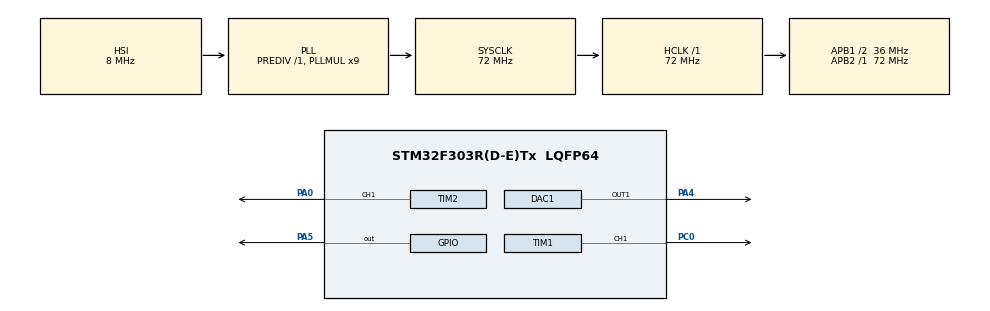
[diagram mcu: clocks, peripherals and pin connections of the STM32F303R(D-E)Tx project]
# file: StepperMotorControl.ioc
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Mcu.Family=STM32F3
Mcu.Name=STM32F303R(D-E)Tx
Mcu.Package=LQFP64
NVIC.PriorityGroup=NVIC_PRIORITYGROUP_4
NVIC.TIM1_CC_IRQn=true\:0\:0\:false\:false\:true\:true\:true\:true
NVIC.TIM6_DAC_IRQn=true\:0\:0\:false\:false\:true\:true\:true\:true
PA0.Signal=S_TIM2_CH1_ETR
PA13.Mode=Serial_Wire
PA13.Signal=SYS_JTMS-SWDIO
PA14.Mode=Serial_Wire
PA14.Signal=SYS_JTCK-SWCLK
PA4.Signal=COMP_DAC11_group
PA5.Signal=GPIO_Output
PC0.Signal=S_TIM1_CH1
PC14-OSC32_IN.Mode=LSE-External-Oscillator
PC14-OSC32_IN.Signal=RCC_OSC32_IN
PC15-OSC32_OUT.Mode=LSE-External-Oscillator
PC15-OSC32_OUT.Signal=RCC_OSC32_OUT
PF0-OSC_IN.Mode=HSE-External-Oscillator
PF0-OSC_IN.Signal=RCC_OSC_IN
PF1-OSC_OUT.Mode=HSE-External-Oscillator
PF1-OSC_OUT.Signal=RCC_OSC_OUT
ProjectManager.HeapSize=0x200
ProjectManager.StackSize=0x400
ProjectManager.TargetToolchain=STM32CubeIDE
RCC.AHBFreq_Value=72000000
RCC.APB1CLKDivider=RCC_HCLK_DIV2
RCC.APB1Freq_Value=36000000
RCC.APB1TimFreq_Value=72000000
RCC.APB2Freq_Value=72000000
RCC.APB2TimFreq_Value=72000000
RCC.CortexFreq_Value=72000000
RCC.HCLKFreq_Value=72000000
RCC.HSE_VALUE=8000000
RCC.HSI_VALUE=8000000
RCC.PLLMUL=RCC_PLL_MUL9
RCC.SYSCLKFreq_VALUE=72000000
RCC.SYSCLKSourceVirtual=RCC_SYSCLKSOURCE_PLLCLK
RCC.USBFreq_Value=72000000
SH.COMP_DAC11_group.0=DAC1_OUT1,DAC_OUT1
SH.S_TIM1_CH1.0=TIM1_CH1,PWM Generation1 CH1
SH.S_TIM2_CH1_ETR.0=TIM2_CH1,PWM Generation1 CH1
TIM1.Channel-PWM\ Generation1\ CH1=TIM_CHANNEL_1
TIM1.Period=999
TIM1.Prescaler=71
TIM1.Pulse-PWM\ Generation1\ CH1=500
TIM2.Channel-PWM\ Generation1\ CH1=TIM_CHANNEL_1
TIM2.Period=999
TIM2.Prescaler=71
TIM2.Pulse-PWM\ Generation1\ CH1=500
VP_TIM1_VS_ClockSourceINT.Mode=Internal
VP_TIM2_VS_ClockSourceINT.Mode=Internal
board=custom

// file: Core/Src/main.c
/* USER CODE BEGIN Header */
/**
  ******************************************************************************
  * @file           : main.c
  * @brief          : Main program body
  ******************************************************************************
  * @attention
  *
  * Copyright (c) 2026 STMicroelectronics.
  * All rights reserved.
  *
  * This software is licensed under terms that can be found in the LICENSE file
  * in the root directory of this software component.
  * If no LICENSE file comes with this software, it is provided AS-IS.
  *
  ******************************************************************************
  */
/* USER CODE END Header */
#include "main.h"

/* USER CODE BEGIN PD */
#define STEPS_PER_DIRECTION  5000U

/* USER CODE END PD */

DAC_HandleTypeDef hdac1;

TIM_HandleTypeDef htim1;
TIM_HandleTypeDef htim2;

/* USER CODE BEGIN PV */
volatile uint32_t step_count = 0;   /* shared with ISR, so volatile */

/* USER CODE END PV */

void SystemClock_Config(void);
static void MX_GPIO_Init(void);
static void MX_DAC1_Init(void);
static void MX_TIM1_Init(void);
static void MX_TIM2_Init(void);

int main(void)
{

  /* MCU Configuration--------------------------------------------------------*/

  /* Reset of all peripherals, Initializes the Flash interface and the Systick. */
  HAL_Init();

  /* Configure the system clock */
  SystemClock_Config();

  /* Initialize all configured peripherals */
  MX_GPIO_Init();
  MX_DAC1_Init();
  MX_TIM1_Init();
  MX_TIM2_Init();
  /* USER CODE BEGIN 2 */
  HAL_DAC_Start(&hdac1, DAC_CHANNEL_1);

  /* _IT version: PWM output plus a CC1 interrupt each time a pulse ends */
  HAL_TIM_PWM_Start_IT(&htim1, TIM_CHANNEL_1);
  HAL_TIM_PWM_Start_IT(&htim2, TIM_CHANNEL_1);
  /* USER CODE END 2 */

  /* Infinite loop */
  while (1)
  {

  }
}

void SystemClock_Config(void)
{
  RCC_OscInitTypeDef RCC_OscInitStruct = {0};
  RCC_ClkInitTypeDef RCC_ClkInitStruct = {0};
  RCC_PeriphCLKInitTypeDef PeriphClkInit = {0};

  /** Initializes the RCC Oscillators according to the specified parameters
  * in the RCC_OscInitTypeDef structure.
  */
  RCC_OscInitStruct.OscillatorType = RCC_OSCILLATORTYPE_HSI;
  RCC_OscInitStruct.HSIState = RCC_HSI_ON;
  RCC_OscInitStruct.HSICalibrationValue = RCC_HSICALIBRATION_DEFAULT;
  RCC_OscInitStruct.PLL.PLLState = RCC_PLL_ON;
  RCC_OscInitStruct.PLL.PLLSource = RCC_PLLSOURCE_HSI;
  RCC_OscInitStruct.PLL.PLLMUL = RCC_PLL_MUL9;
  RCC_OscInitStruct.PLL.PREDIV = RCC_PREDIV_DIV1;
  if (HAL_RCC_OscConfig(&RCC_OscInitStruct) != HAL_OK)
  {
    Error_Handler();
  }

  /** Initializes the CPU, AHB and APB buses clocks
  */
  RCC_ClkInitStruct.ClockType = RCC_CLOCKTYPE_HCLK|RCC_CLOCKTYPE_SYSCLK
                              |RCC_CLOCKTYPE_PCLK1|RCC_CLOCKTYPE_PCLK2;
  RCC_ClkInitStruct.SYSCLKSource = RCC_SYSCLKSOURCE_PLLCLK;
  RCC_ClkInitStruct.AHBCLKDivider = RCC_SYSCLK_DIV1;
  RCC_ClkInitStruct.APB1CLKDivider = RCC_HCLK_DIV2;
  RCC_ClkInitStruct.APB2CLKDivider = RCC_HCLK_DIV1;

  if (HAL_RCC_ClockConfig(&RCC_ClkInitStruct, FLASH_LATENCY_2) != HAL_OK)
  {
    Error_Handler();
  }
  PeriphClkInit.PeriphClockSelection = RCC_PERIPHCLK_TIM1|RCC_PERIPHCLK_TIM2;
  PeriphClkInit.Tim1ClockSelection = RCC_TIM1CLK_HCLK;
  PeriphClkInit.Tim2ClockSelection = RCC_TIM2CLK_HCLK;
  if (HAL_RCCEx_PeriphCLKConfig(&PeriphClkInit) != HAL_OK)
  {
    Error_Handler();
  }
}

static void MX_DAC1_Init(void)
{

  DAC_ChannelConfTypeDef sConfig = {0};

  /** DAC Initialization
  */
  hdac1.Instance = DAC1;
  if (HAL_DAC_Init(&hdac1) != HAL_OK)
  {
    Error_Handler();
  }

  /** DAC channel OUT1 config
  */
  sConfig.DAC_Trigger = DAC_TRIGGER_NONE;
  sConfig.DAC_OutputBuffer = DAC_OUTPUTBUFFER_ENABLE;
  if (HAL_DAC_ConfigChannel(&hdac1, &sConfig, DAC_CHANNEL_1) != HAL_OK)
  {
    Error_Handler();
  }

}

static void MX_TIM1_Init(void)
{

  TIM_ClockConfigTypeDef sClockSourceConfig = {0};
  TIM_MasterConfigTypeDef sMasterConfig = {0};
  TIM_OC_InitTypeDef sConfigOC = {0};
  TIM_BreakDeadTimeConfigTypeDef sBreakDeadTimeConfig = {0};

  htim1.Instance = TIM1;
  htim1.Init.Prescaler = 71;
  htim1.Init.CounterMode = TIM_COUNTERMODE_UP;
  htim1.Init.Period = 999;
  htim1.Init.ClockDivision = TIM_CLOCKDIVISION_DIV1;
  htim1.Init.RepetitionCounter = 0;
  htim1.Init.AutoReloadPreload = TIM_AUTORELOAD_PRELOAD_DISABLE;
  if (HAL_TIM_Base_Init(&htim1) != HAL_OK)
  {
    Error_Handler();
  }
  sClockSourceConfig.ClockSource = TIM_CLOCKSOURCE_INTERNAL;
  if (HAL_TIM_ConfigClockSource(&htim1, &sClockSourceConfig) != HAL_OK)
  {
    Error_Handler();
  }
  if (HAL_TIM_PWM_Init(&htim1) != HAL_OK)
  {
    Error_Handler();
  }
  sMasterConfig.MasterOutputTrigger = TIM_TRGO_RESET;
  sMasterConfig.MasterOutputTrigger2 = TIM_TRGO2_RESET;
  sMasterConfig.MasterSlaveMode = TIM_MASTERSLAVEMODE_DISABLE;
  if (HAL_TIMEx_MasterConfigSynchronization(&htim1, &sMasterConfig) != HAL_OK)
  {
    Error_Handler();
  }
  sConfigOC.OCMode = TIM_OCMODE_PWM1;
  sConfigOC.Pulse = 500;
  sConfigOC.OCPolarity = TIM_OCPOLARITY_HIGH;
  sConfigOC.OCNPolarity = TIM_OCNPOLARITY_HIGH;
  sConfigOC.OCFastMode = TIM_OCFAST_DISABLE;
  sConfigOC.OCIdleState = TIM_OCIDLESTATE_RESET;
  sConfigOC.OCNIdleState = TIM_OCNIDLESTATE_RESET;
  if (HAL_TIM_PWM_ConfigChannel(&htim1, &sConfigOC, TIM_CHANNEL_1) != HAL_OK)
  {
    Error_Handler();
  }
  sBreakDeadTimeConfig.OffStateRunMode = TIM_OSSR_DISABLE;
  sBreakDeadTimeConfig.OffStateIDLEMode = TIM_OSSI_DISABLE;
  sBreakDeadTimeConfig.LockLevel = TIM_LOCKLEVEL_OFF;
  sBreakDeadTimeConfig.DeadTime = 0;
  sBreakDeadTimeConfig.BreakState = TIM_BREAK_DISABLE;
  sBreakDeadTimeConfig.BreakPolarity = TIM_BREAKPOLARITY_HIGH;
  sBreakDeadTimeConfig.BreakFilter = 0;
  sBreakDeadTimeConfig.Break2State = TIM_BREAK2_DISABLE;
  sBreakDeadTimeConfig.Break2Polarity = TIM_BREAK2POLARITY_HIGH;
  sBreakDeadTimeConfig.Break2Filter = 0;
  sBreakDeadTimeConfig.AutomaticOutput = TIM_AUTOMATICOUTPUT_DISABLE;
  if (HAL_TIMEx_ConfigBreakDeadTime(&htim1, &sBreakDeadTimeConfig) != HAL_OK)
  {
    Error_Handler();
  }
  HAL_TIM_MspPostInit(&htim1);

}

static void MX_TIM2_Init(void)
{

  TIM_ClockConfigTypeDef sClockSourceConfig = {0};
  TIM_MasterConfigTypeDef sMasterConfig = {0};
  TIM_OC_InitTypeDef sConfigOC = {0};

  htim2.Instance = TIM2;
  htim2.Init.Prescaler = 71;
  htim2.Init.CounterMode = TIM_COUNTERMODE_UP;
  htim2.Init.Period = 999;
  htim2.Init.ClockDivision = TIM_CLOCKDIVISION_DIV1;
  htim2.Init.AutoReloadPreload = TIM_AUTORELOAD_PRELOAD_DISABLE;
  if (HAL_TIM_Base_Init(&htim2) != HAL_OK)
  {
    Error_Handler();
  }
  sClockSourceConfig.ClockSource = TIM_CLOCKSOURCE_INTERNAL;
  if (HAL_TIM_ConfigClockSource(&htim2, &sClockSourceConfig) != HAL_OK)
  {
    Error_Handler();
  }
  if (HAL_TIM_PWM_Init(&htim2) != HAL_OK)
  {
    Error_Handler();
  }
  sMasterConfig.MasterOutputTrigger = TIM_TRGO_RESET;
  sMasterConfig.MasterSlaveMode = TIM_MASTERSLAVEMODE_DISABLE;
  if (HAL_TIMEx_MasterConfigSynchronization(&htim2, &sMasterConfig) != HAL_OK)
  {
    Error_Handler();
  }
  sConfigOC.OCMode = TIM_OCMODE_PWM1;
  sConfigOC.Pulse = 500;
  sConfigOC.OCPolarity = TIM_OCPOLARITY_HIGH;
  sConfigOC.OCFastMode = TIM_OCFAST_DISABLE;
  if (HAL_TIM_PWM_ConfigChannel(&htim2, &sConfigOC, TIM_CHANNEL_1) != HAL_OK)
  {
    Error_Handler();
  }
  HAL_TIM_MspPostInit(&htim2);

}

static void MX_GPIO_Init(void)
{
  GPIO_InitTypeDef GPIO_InitStruct = {0};

  /* GPIO Ports Clock Enable */
  __HAL_RCC_GPIOC_CLK_ENABLE();
  __HAL_RCC_GPIOF_CLK_ENABLE();
  __HAL_RCC_GPIOA_CLK_ENABLE();

  /*Configure GPIO pin Output Level */
  HAL_GPIO_WritePin(GPIOA, GPIO_PIN_5, GPIO_PIN_RESET);

  /*Configure GPIO pin : PA5 */
  GPIO_InitStruct.Pin = GPIO_PIN_5;
  GPIO_InitStruct.Mode = GPIO_MODE_OUTPUT_PP;
  GPIO_InitStruct.Pull = GPIO_NOPULL;
  GPIO_InitStruct.Speed = GPIO_SPEED_FREQ_LOW;
  HAL_GPIO_Init(GPIOA, &GPIO_InitStruct);

}

/* USER CODE BEGIN 4 */
/**
  * Called on TIM1 CH1 compare match, i.e. the falling edge of each STEP pulse.
  * Toggling DIR here (not at the rising edge) gives the driver ~500 us of
  * DIR setup time before the next step.
  */
void HAL_TIM_PWM_PulseFinishedCallback(TIM_HandleTypeDef *htim)
{
  if (htim->Instance == TIM1 && htim->Channel == HAL_TIM_ACTIVE_CHANNEL_1)
  {
    step_count++;
    if (step_count >= STEPS_PER_DIRECTION)
    {
      step_count = 0;
      HAL_GPIO_TogglePin(GPIOA, GPIO_PIN_5);   /* DIR+ */
    }
  }
}

/* USER CODE END 4 */

void Error_Handler(void)
{
  __disable_irq();
  while (1)
  {
  }
}
